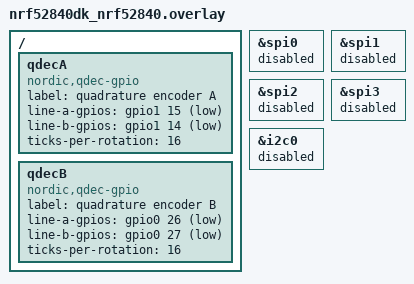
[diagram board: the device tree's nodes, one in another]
/* SPDX-License-Identifier: Apache-2.0 */
&spi0 {
	status="disabled";
};
&spi1 {
	status="disabled";
};
&spi2 {
	status = "disabled";
};
&spi3 {
	status = "disabled";
};
&i2c0 {
	status="disabled";
};

/ {
	qdecA: qdecA {
		compatible = "nordic,qdec-gpio";
		status = "okay";
		label = "quadrature encoder A";
		/* Right Side Encoder */
		/* line-a: Back */
		/* line-b: Front */
		line-a-gpios = <&gpio1 15 (GPIO_ACTIVE_LOW)>;
		line-b-gpios = <&gpio1 14 (GPIO_ACTIVE_LOW)>;
		ticks-per-rotation = <16>;
	};

	qdecB: qdecB {
		compatible = "nordic,qdec-gpio";
		status = "okay";
		label = "quadrature encoder B";
		/* Left Side Encoder */
		/* line-a: Back */
		/* line-b: Front */
		line-a-gpios = <&gpio0 26 (GPIO_ACTIVE_LOW)>;
		line-b-gpios = <&gpio0 27 (GPIO_ACTIVE_LOW)>;
		ticks-per-rotation = <16>;
	};
};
